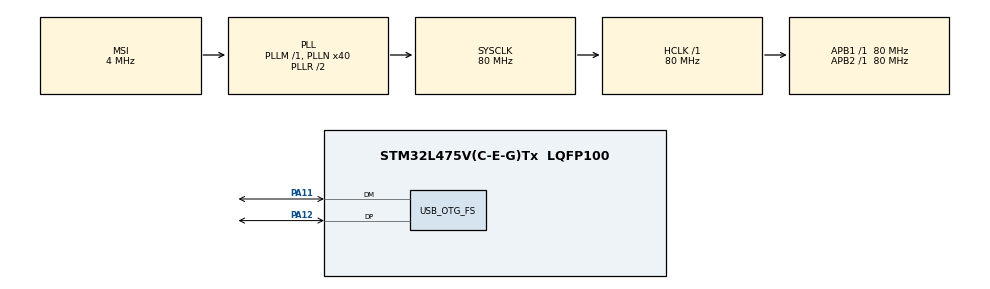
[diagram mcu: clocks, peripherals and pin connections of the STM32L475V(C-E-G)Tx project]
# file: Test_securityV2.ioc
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Mcu.Family=STM32L4
RCC.MSI_VALUE=4000000
USB_DEVICE.CLASS_NAME_FS=CDC
RCC.CortexFreq_Value=80000000
USB_DEVICE.VirtualModeFS=Cdc_FS
PH0-OSC_IN\ (PH0).Signal=RCC_OSC_IN
PA11.Mode=Device_Only
VP_RNG_VS_RNG.Mode=RNG_Activate
PH1-OSC_OUT\ (PH1).Signal=RCC_OSC_OUT
RCC.SYSCLKSource=RCC_SYSCLKSOURCE_PLLCLK
ProjectManager.StackSize=0x400
PA12.Signal=USB_OTG_FS_DP
ProjectManager.TargetToolchain=STM32CubeIDE
RCC.HCLKFreq_Value=80000000
VP_USB_DEVICE_VS_USB_DEVICE_CDC_FS.Mode=CDC_FS
RCC.APB2TimFreq_Value=80000000
RCC.USBFreq_Value=48000000
RCC.LSE_VALUE=32768
RCC.AHBFreq_Value=80000000
PH1-OSC_OUT\ (PH1).Mode=HSE-External-Oscillator
RCC.HSE_VALUE=8000000
board=custom
RCC.VCOOutputFreq_Value=160000000
RCC.APB2Freq_Value=80000000
VP_SYS_VS_tim1.Mode=TIM1
RCC.ADCFreq_Value=48000000
Mcu.Name=STM32L475V(C-E-G)Tx
RCC.SYSCLKFreq_VALUE=80000000
Mcu.Package=LQFP100
NVIC.TimeBase=TIM1_UP_TIM16_IRQn
PA12.Mode=Device_Only
NVIC.OTG_FS_IRQn=true\:0\:0\:false\:false\:true\:false\:true
PA11.Signal=USB_OTG_FS_DM
NVIC.TimeBaseIP=TIM1
USB_OTG_FS.VirtualMode=Device_Only
ProjectManager.HeapSize=0x200
RCC.HSI_VALUE=16000000
NVIC.TIM1_UP_TIM16_IRQn=true\:0\:0\:false\:false\:true\:false\:true
NVIC.PriorityGroup=NVIC_PRIORITYGROUP_4
RCC.PLLN=40
RCC.APB1TimFreq_Value=80000000
RCC.APB1Freq_Value=80000000
VP_CRC_VS_CRC.Mode=CRC_Activate
USB_DEVICE.VirtualMode=Cdc
PH0-OSC_IN\ (PH0).Mode=HSE-External-Oscillator
RCC.PLLSAI1N=24

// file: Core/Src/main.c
/* USER CODE END Header */
#include "main.h"
#include "usb_device.h"

/* USER CODE BEGIN Includes */
#include "stdio.h"
#include "string.h"
#include "stdlib.h"
#include "time.h"
/* USER CODE END Includes */

/* USER CODE BEGIN PD */
#define PLAINTEXT_LENGTH 64
#define CRL_AES192_KEY	24
/* USER CODE END PD */

/* USER CODE BEGIN PM */

const uint8_t Plaintext[PLAINTEXT_LENGTH] =
  {
    0x6b, 0xc1, 0xbe, 0xe2, 0x2e, 0x40, 0x9f, 0x96,
    0xe9, 0x3d, 0x7e, 0x11, 0x73, 0x93, 0x17, 0x2a,
    0xae, 0x2d, 0x8a, 0x57, 0x1e, 0x03, 0xac, 0x9c,
    0x9e, 0xb7, 0x6f, 0xac, 0x45, 0xaf, 0x8e, 0x51,
    0x30, 0xc8, 0x1c, 0x46, 0xa3, 0x5c, 0xe4, 0x11,
    0xe5, 0xfb, 0xc1, 0x19, 0x1a, 0x0a, 0x52, 0xef,
    0xf6, 0x9f, 0x24, 0x45, 0xdf, 0x4f, 0x9b, 0x17,
    0xad, 0x2b, 0x41, 0x7b, 0xe6, 0x6c, 0x37, 0x11
  };

/* Key to be used for AES encryption/decryption */
uint8_t Sym_Key[CRL_AES192_KEY] =
  {
    0x8e, 0x73, 0xb0, 0xf7, 0xda, 0x0e, 0x64, 0x52,
    0xc8, 0x10, 0xf3, 0x2b, 0x80, 0x90, 0x79, 0xe5,
    0x62, 0xf8, 0xea, 0xd2, 0x52, 0x2c, 0x6b, 0x7b,
  };

uint8_t Random_key[24];

/* USER CODE END PM */

CRC_HandleTypeDef hcrc;

RNG_HandleTypeDef hrng;

void SystemClock_Config(void);
static void MX_GPIO_Init(void);
static void MX_RNG_Init(void);
static void MX_CRC_Init(void);
void Key_Generate(uint8_t Key_length);

/* USER CODE BEGIN 0 */
int _write(int file, char *ptr, int len)
{
	int i=0;
	for (i = 0; i<len; i++)
		ITM_SendChar((*ptr++));
	return len;
}
/* USER CODE END 0 */

int main(void)
{
  /* USER CODE BEGIN 1 */
  error_t Error;
  AesContext Aes_Handler;
  /* USER CODE END 1 */

  /* MCU Configuration--------------------------------------------------------*/

  /* Reset of all peripherals, Initializes the Flash interface and the Systick. */
  HAL_Init();

  /* Configure the system clock */
  SystemClock_Config();

  /* Initialize all configured peripherals */
  MX_GPIO_Init();
  MX_RNG_Init();
  //MX_USB_DEVICE_Init();
  MX_CRC_Init();

  /* USER CODE BEGIN 2 */
  /* Encrypt data */

  /* Buffer to store the output data */
  uint8_t Encrypted_data[192];

  uint8_t Decrypted_data[64];

  //Generate a random key
  Key_Generate(24);

  // Initialize AES Context by using a random symmetric key
  Error = aesInit(&Aes_Handler, Random_key, CRL_AES192_KEY);
  if(Error != NO_ERROR )
  {
	  Error_Handler();
  }

  // Encrypt data
  aesEncryptBlock(&Aes_Handler, Plaintext, Encrypted_data);

  // Decrypt Data
  aesDecryptBlock(&Aes_Handler, Encrypted_data, Decrypted_data);

  /* USER CODE END 2 */

  /* Infinite loop */
  /* USER CODE BEGIN WHILE */
  while (1)
  {
	  HAL_GPIO_TogglePin(GPIOA, GPIO_PIN_5);
	  HAL_Delay(2000);
  }
  /* USER CODE END 3 */
}

void SystemClock_Config(void)
{
  RCC_OscInitTypeDef RCC_OscInitStruct = {0};
  RCC_ClkInitTypeDef RCC_ClkInitStruct = {0};
  RCC_PeriphCLKInitTypeDef PeriphClkInit = {0};

  /** Initializes the RCC Oscillators according to the specified parameters
  * in the RCC_OscInitTypeDef structure.
  */
  RCC_OscInitStruct.OscillatorType = RCC_OSCILLATORTYPE_MSI;
  RCC_OscInitStruct.MSIState = RCC_MSI_ON;
  RCC_OscInitStruct.MSICalibrationValue = 0;
  RCC_OscInitStruct.MSIClockRange = RCC_MSIRANGE_6;
  RCC_OscInitStruct.PLL.PLLState = RCC_PLL_ON;
  RCC_OscInitStruct.PLL.PLLSource = RCC_PLLSOURCE_MSI;
  RCC_OscInitStruct.PLL.PLLM = 1;
  RCC_OscInitStruct.PLL.PLLN = 40;
  RCC_OscInitStruct.PLL.PLLP = RCC_PLLP_DIV7;
  RCC_OscInitStruct.PLL.PLLQ = RCC_PLLQ_DIV2;
  RCC_OscInitStruct.PLL.PLLR = RCC_PLLR_DIV2;
  if (HAL_RCC_OscConfig(&RCC_OscInitStruct) != HAL_OK)
  {
    Error_Handler();
  }
  /** Initializes the CPU, AHB and APB buses clocks
  */
  RCC_ClkInitStruct.ClockType = RCC_CLOCKTYPE_HCLK|RCC_CLOCKTYPE_SYSCLK
                              |RCC_CLOCKTYPE_PCLK1|RCC_CLOCKTYPE_PCLK2;
  RCC_ClkInitStruct.SYSCLKSource = RCC_SYSCLKSOURCE_PLLCLK;
  RCC_ClkInitStruct.AHBCLKDivider = RCC_SYSCLK_DIV1;
  RCC_ClkInitStruct.APB1CLKDivider = RCC_HCLK_DIV1;
  RCC_ClkInitStruct.APB2CLKDivider = RCC_HCLK_DIV1;

  if (HAL_RCC_ClockConfig(&RCC_ClkInitStruct, FLASH_LATENCY_4) != HAL_OK)
  {
    Error_Handler();
  }
  PeriphClkInit.PeriphClockSelection = RCC_PERIPHCLK_USB|RCC_PERIPHCLK_RNG;
  PeriphClkInit.UsbClockSelection = RCC_USBCLKSOURCE_PLLSAI1;
  PeriphClkInit.RngClockSelection = RCC_RNGCLKSOURCE_PLLSAI1;
  PeriphClkInit.PLLSAI1.PLLSAI1Source = RCC_PLLSOURCE_MSI;
  PeriphClkInit.PLLSAI1.PLLSAI1M = 1;
  PeriphClkInit.PLLSAI1.PLLSAI1N = 24;
  PeriphClkInit.PLLSAI1.PLLSAI1P = RCC_PLLP_DIV7;
  PeriphClkInit.PLLSAI1.PLLSAI1Q = RCC_PLLQ_DIV2;
  PeriphClkInit.PLLSAI1.PLLSAI1R = RCC_PLLR_DIV2;
  PeriphClkInit.PLLSAI1.PLLSAI1ClockOut = RCC_PLLSAI1_48M2CLK;
  if (HAL_RCCEx_PeriphCLKConfig(&PeriphClkInit) != HAL_OK)
  {
    Error_Handler();
  }
  /** Configure the main internal regulator output voltage
  */
  if (HAL_PWREx_ControlVoltageScaling(PWR_REGULATOR_VOLTAGE_SCALE1) != HAL_OK)
  {
    Error_Handler();
  }
}

void MX_CRC_Init(void)
{

	hcrc.Instance = CRC;
	hcrc.Init.DefaultInitValueUse = DEFAULT_POLYNOMIAL_ENABLE;
	hcrc.Init.DefaultInitValueUse = DEFAULT_INIT_VALUE_ENABLE;
	hcrc.Init.InputDataInversionMode = CRC_INPUTDATA_INVERSION_NONE;
	hcrc.Init.OutputDataInversionMode = CRC_OUTPUTDATA_INVERSION_DISABLE;
	if(HAL_CRC_Init(&hcrc) != HAL_OK)
	{
		Error_Handler();
	}

}

static void MX_RNG_Init(void)
{

  hrng.Instance = RNG;
  if (HAL_RNG_Init(&hrng) != HAL_OK)
  {
    Error_Handler();
  }

}

static void MX_GPIO_Init(void)
{
  GPIO_InitTypeDef GPIO_InitStruct = {0};

  /* GPIO Ports Clock Enable */
  __HAL_RCC_GPIOH_CLK_ENABLE();
  __HAL_RCC_GPIOA_CLK_ENABLE();

  /*Configure GPIO pin Output Level */
  HAL_GPIO_WritePin(GPIOA, GPIO_PIN_5, GPIO_PIN_RESET);

  /*Configure GPIO pin : PA5 */
  GPIO_InitStruct.Pin = GPIO_PIN_5;
  GPIO_InitStruct.Mode = GPIO_MODE_OUTPUT_PP;
  GPIO_InitStruct.Pull = GPIO_NOPULL;
  GPIO_InitStruct.Speed = GPIO_SPEED_FREQ_LOW;
  HAL_GPIO_Init(GPIOA, &GPIO_InitStruct);

}

/* USER CODE BEGIN 4 */
void Key_Generate(uint8_t Key_length)
{
	// Generate a random number between 0 and 255 (8-bit number)
    for (int i=0 ; i< Key_length ; i++)
    {
    	Random_key[i] = (uint8_t)(rand() % 256);
    }
}
/* USER CODE END 4 */

void Error_Handler(void)
{
  __disable_irq();
  while (1)
  {
  }
}

/************************ (C) COPYRIGHT STMicroelectronics *****END OF FILE****/
